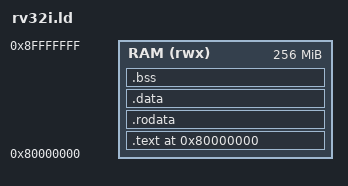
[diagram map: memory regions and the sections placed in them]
OUTPUT_ARCH(riscv)
ENTRY(_start)

MEMORY
{
    RAM (rwx) : ORIGIN = 0x80000000, LENGTH = 256M
}

SECTIONS
{
    . = 0x80000000;
    
    .text : {
        *(.text.init)
        *(.text)
        *(.text.*)
        . = ALIGN(4);
    } > RAM

    .rodata : {
        *(.rodata)
        *(.rodata.*)
        . = ALIGN(4);
    } > RAM

    .data : {
        *(.data)
        *(.data.*)
        . = ALIGN(4);
    } > RAM

    .bss : {
        __bss_start = .;
        *(.bss)
        *(.bss.*)
        *(COMMON)
        . = ALIGN(4);
        __bss_end = .;
    } > RAM

    . = ALIGN(4);
    __stack_top = 0x80100000;
}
